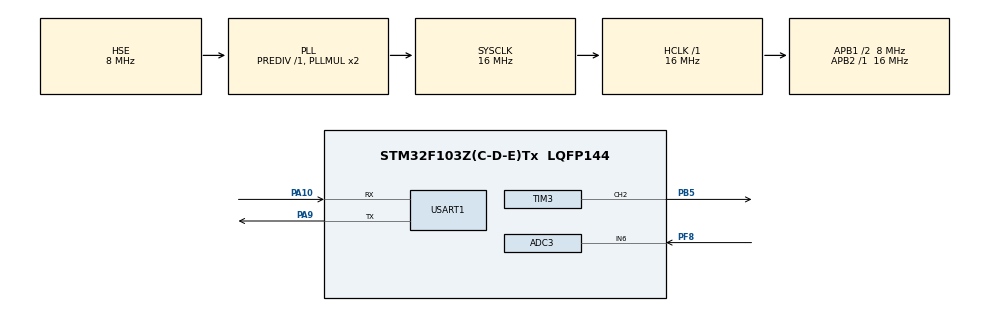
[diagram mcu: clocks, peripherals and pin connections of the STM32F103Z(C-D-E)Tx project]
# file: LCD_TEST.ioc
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ADC3.Channel-0\#ChannelRegularConversion=ADC_CHANNEL_6
ADC3.ContinuousConvMode=ENABLE
ADC3.NbrOfConversionFlag=1
ADC3.Rank-0\#ChannelRegularConversion=1
ADC3.SamplingTime-0\#ChannelRegularConversion=ADC_SAMPLETIME_1CYCLE_5
Dma.ADC3.0.Direction=DMA_PERIPH_TO_MEMORY
Dma.ADC3.0.Instance=DMA2_Channel5
Dma.ADC3.0.MemDataAlignment=DMA_MDATAALIGN_HALFWORD
Dma.ADC3.0.MemInc=DMA_MINC_ENABLE
Dma.ADC3.0.Mode=DMA_NORMAL
Dma.ADC3.0.PeriphDataAlignment=DMA_PDATAALIGN_HALFWORD
Dma.ADC3.0.PeriphInc=DMA_PINC_DISABLE
Dma.ADC3.0.Priority=DMA_PRIORITY_LOW
Dma.Request0=ADC3
Mcu.Family=STM32F1
Mcu.Name=STM32F103Z(C-D-E)Tx
Mcu.Package=LQFP144
NVIC.ADC3_IRQn=true\:0\:0\:false\:false\:true\:true\:true\:true
NVIC.DMA2_Channel4_5_IRQn=true\:0\:0\:false\:false\:true\:false\:true\:true
NVIC.PriorityGroup=NVIC_PRIORITYGROUP_4
NVIC.TIM2_IRQn=true\:0\:0\:false\:false\:true\:true\:true\:true
NVIC.TIM3_IRQn=true\:0\:0\:false\:false\:true\:true\:true\:true
NVIC.USART1_IRQn=true\:0\:0\:false\:false\:true\:true\:true\:true
OSC_IN.Mode=HSE-External-Oscillator
OSC_IN.Signal=RCC_OSC_IN
OSC_OUT.Mode=HSE-External-Oscillator
OSC_OUT.Signal=RCC_OSC_OUT
PA10.Mode=Asynchronous
PA10.Signal=USART1_RX
PA13.Mode=Serial_Wire
PA13.Signal=SYS_JTMS-SWDIO
PA14.Mode=Serial_Wire
PA14.Signal=SYS_JTCK-SWCLK
PA9.Mode=Asynchronous
PA9.Signal=USART1_TX
PB5.Signal=S_TIM3_CH2
PC14-OSC32_IN.Mode=LSE-External-Oscillator
PC14-OSC32_IN.Signal=RCC_OSC32_IN
PC15-OSC32_OUT.Mode=LSE-External-Oscillator
PC15-OSC32_OUT.Signal=RCC_OSC32_OUT
PF8.Mode=IN6
PF8.Signal=ADC3_IN6
ProjectManager.HeapSize=0x200
ProjectManager.StackSize=0x400
ProjectManager.TargetToolchain=MDK-ARM V5.32
RCC.AHBFreq_Value=16000000
RCC.APB1CLKDivider=RCC_HCLK_DIV2
RCC.APB1Freq_Value=8000000
RCC.APB1TimFreq_Value=16000000
RCC.APB2Freq_Value=16000000
RCC.APB2TimFreq_Value=16000000
RCC.HCLKFreq_Value=16000000
RCC.PLLSourceVirtual=RCC_PLLSOURCE_HSE
RCC.RTCClockSelection=RCC_RTCCLKSOURCE_LSE
RCC.SYSCLKFreq_VALUE=16000000
RCC.SYSCLKSource=RCC_SYSCLKSOURCE_PLLCLK
RCC.USBFreq_Value=16000000
RTC.Date=24
RTC.Hours=18
RTC.Month=RTC_MONTH_OCTOBER
RTC.WeekDay=RTC_WEEKDAY_THURSDAY
RTC.Year=24
SH.S_TIM3_CH2.0=TIM3_CH2,PWM Generation2 CH2
TIM2.AutoReloadPreload=TIM_AUTORELOAD_PRELOAD_ENABLE
TIM2.Period=5000 -1
TIM2.Prescaler=7200-1
TIM3.AutoReloadPreload=TIM_AUTORELOAD_PRELOAD_ENABLE
TIM3.Channel-PWM\ Generation2\ CH2=TIM_CHANNEL_2
TIM3.OC2Preload_PWM=ENABLE
TIM3.OCPolarity_2=TIM_OCPOLARITY_LOW
TIM3.Period=300
TIM3.Prescaler=72-1
USART1.VirtualMode=VM_ASYNC
VP_RTC_No_RTC_Output.Mode=RTC_OUT_NO
VP_RTC_VS_RTC_Activate.Mode=RTC_Enabled
VP_RTC_VS_RTC_Calendar.Mode=RTC_Calendar
VP_TIM2_VS_ClockSourceINT.Mode=Internal
VP_TIM3_VS_ClockSourceINT.Mode=Internal
board=custom

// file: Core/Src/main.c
/* USER CODE BEGIN Header */
/**
  ******************************************************************************
  * @file           : main.c
  * @brief          : Main program body
  ******************************************************************************
  * @attention
  *
  * Copyright (c) 2024 STMicroelectronics.
  * All rights reserved.
  *
  * This software is licensed under terms that can be found in the LICENSE file
  * in the root directory of this software component.
  * If no LICENSE file comes with this software, it is provided AS-IS.
  *
  ******************************************************************************
  */
/* USER CODE END Header */
#include "main.h"
#include "adc.h"
#include "dma.h"
#include "rtc.h"
#include "tim.h"
#include "usart.h"
#include "gpio.h"

/* USER CODE BEGIN Includes */
#include "stdio.h"
#include "pwm_led.h"
#include "rtc_test.h"
#include "light_adc.h"
#include "string.h"
/* USER CODE END Includes */

void SystemClock_Config(void);
/* USER CODE BEGIN PFP */
int fputc(int ch,FILE *f){
 uint8_t temp[1]={ch};
 HAL_UART_Transmit(&huart1,temp,1,HAL_MAX_DELAY);
 return ch;
}
/* USER CODE END PFP */

int main(void)
{

  /* MCU Configuration--------------------------------------------------------*/

  /* Reset of all peripherals, Initializes the Flash interface and the Systick. */
  HAL_Init();

  /* Configure the system clock */
  SystemClock_Config();

  /* Initialize all configured peripherals */
  MX_GPIO_Init();
  MX_DMA_Init();
  MX_TIM2_Init();
  MX_TIM3_Init();
  MX_RTC_Init();
  MX_USART1_UART_Init();
  MX_ADC3_Init();
  /* USER CODE BEGIN 2 */
//  HAL_TIM_Base_Start_IT(&htim2);
   HAL_ADC_Start(&hadc3);
  HAL_TIM_PWM_Start(&htim3, TIM_CHANNEL_2);

  HAL_UART_Transmit(&huart1, (uint8_t *)"hello\r\n", 5, HAL_MAX_DELAY);
  /* USER CODE END 2 */

  /* Infinite loop */
  /* USER CODE BEGIN WHILE */
  while (1)
  {
//      pwm_led_on();
//      rtc_time_get();

      light_value_get();

        HAL_Delay(1000);
    /* USER CODE END WHILE */

  }
}

void SystemClock_Config(void)
{
  RCC_OscInitTypeDef RCC_OscInitStruct = {0};
  RCC_ClkInitTypeDef RCC_ClkInitStruct = {0};
  RCC_PeriphCLKInitTypeDef PeriphClkInit = {0};

  /** Initializes the RCC Oscillators according to the specified parameters
  * in the RCC_OscInitTypeDef structure.
  */
  RCC_OscInitStruct.OscillatorType = RCC_OSCILLATORTYPE_HSE|RCC_OSCILLATORTYPE_LSE;
  RCC_OscInitStruct.HSEState = RCC_HSE_ON;
  RCC_OscInitStruct.HSEPredivValue = RCC_HSE_PREDIV_DIV1;
  RCC_OscInitStruct.LSEState = RCC_LSE_ON;
  RCC_OscInitStruct.HSIState = RCC_HSI_ON;
  RCC_OscInitStruct.PLL.PLLState = RCC_PLL_ON;
  RCC_OscInitStruct.PLL.PLLSource = RCC_PLLSOURCE_HSE;
  RCC_OscInitStruct.PLL.PLLMUL = RCC_PLL_MUL2;
  if (HAL_RCC_OscConfig(&RCC_OscInitStruct) != HAL_OK)
  {
    Error_Handler();
  }

  /** Initializes the CPU, AHB and APB buses clocks
  */
  RCC_ClkInitStruct.ClockType = RCC_CLOCKTYPE_HCLK|RCC_CLOCKTYPE_SYSCLK
                              |RCC_CLOCKTYPE_PCLK1|RCC_CLOCKTYPE_PCLK2;
  RCC_ClkInitStruct.SYSCLKSource = RCC_SYSCLKSOURCE_PLLCLK;
  RCC_ClkInitStruct.AHBCLKDivider = RCC_SYSCLK_DIV1;
  RCC_ClkInitStruct.APB1CLKDivider = RCC_HCLK_DIV2;
  RCC_ClkInitStruct.APB2CLKDivider = RCC_HCLK_DIV1;

  if (HAL_RCC_ClockConfig(&RCC_ClkInitStruct, FLASH_LATENCY_0) != HAL_OK)
  {
    Error_Handler();
  }
  PeriphClkInit.PeriphClockSelection = RCC_PERIPHCLK_RTC|RCC_PERIPHCLK_ADC;
  PeriphClkInit.RTCClockSelection = RCC_RTCCLKSOURCE_LSE;
  PeriphClkInit.AdcClockSelection = RCC_ADCPCLK2_DIV2;
  if (HAL_RCCEx_PeriphCLKConfig(&PeriphClkInit) != HAL_OK)
  {
    Error_Handler();
  }
}

void Error_Handler(void)
{
  __disable_irq();
  while (1)
  {
  }
}
